AUTOSAR XML (schema 4-0-3)
package /ComponentTypes
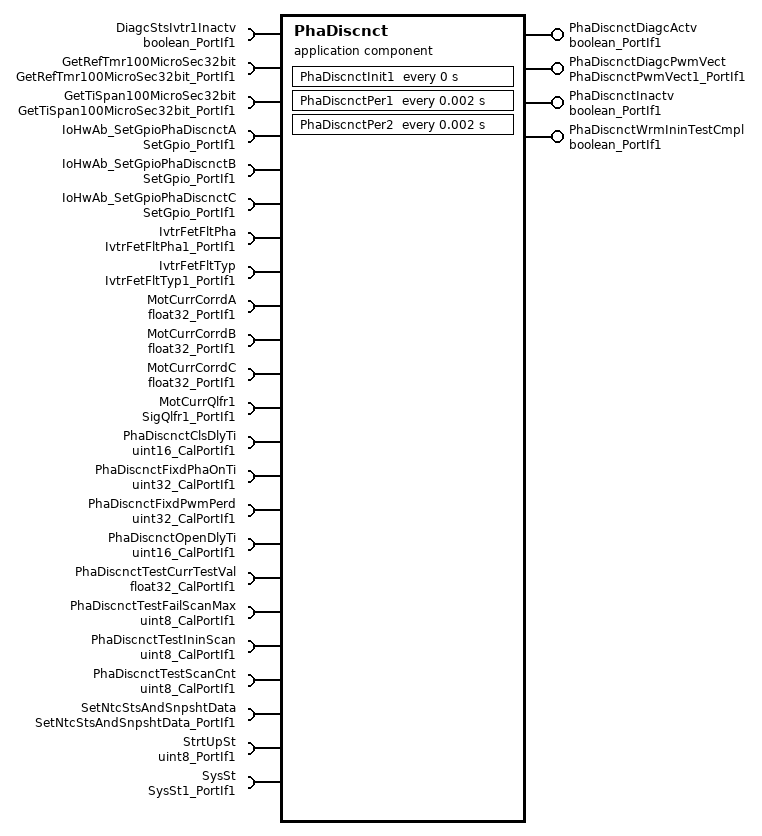
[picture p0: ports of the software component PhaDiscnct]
  application sw component type PhaDiscnct
    4 x provide port:
      PhaDiscnctDiagcActv: nonqueued-sender-com-spec{data-element=Logl, init-value=0}, provided-interface=boolean_PortIf1  # Signal used to signal request of control over Timer PWM on times
      PhaDiscnctDiagcPwmVect: nonqueued-sender-com-spec{data-element=Val, init-value=0}, provided-interface=PhaDiscnctPwmVect1_PortIf1
      PhaDiscnctInactv: nonqueued-sender-com-spec{data-element=Logl, init-value=0}, provided-interface=boolean_PortIf1  # Signal used to indicate that Phase Disconnect functionality is not active
      PhaDiscnctWrmIninTestCmpl: nonqueued-sender-com-spec{data-element=Logl, init-value=0}, provided-interface=boolean_PortIf1  # Signal used to indicate phase disconnect warm init test completed
    23 x require port:
      DiagcStsIvtr1Inactv: nonqueued-receiver-com-spec{data-element=Logl, filter=data-filter-type=ALWAYS, init-value=0}, required-interface=boolean_PortIf1  # Diagnostic Status Inverter 1 Inactive
      GetRefTmr100MicroSec32bit: client-com-spec=Oper, required-interface=GetRefTmr100MicroSec32bit_PortIf1  # System Time Server call
      GetTiSpan100MicroSec32bit: client-com-spec=Oper, required-interface=GetTiSpan100MicroSec32bit_PortIf1  # Calculate System Time Span Server call
      IoHwAb_SetGpioPhaDiscnctA: client-com-spec=Oper, required-interface=SetGpio_PortIf1
      IoHwAb_SetGpioPhaDiscnctB: client-com-spec=Oper, required-interface=SetGpio_PortIf1
      IoHwAb_SetGpioPhaDiscnctC: client-com-spec=Oper, required-interface=SetGpio_PortIf1
      IvtrFetFltPha: nonqueued-receiver-com-spec{data-element=Val, filter=data-filter-type=ALWAYS, init-value=0}, required-interface=IvtrFetFltPha1_PortIf1
      IvtrFetFltTyp: nonqueued-receiver-com-spec{data-element=Val, filter=data-filter-type=ALWAYS, init-value=0}, required-interface=IvtrFetFltTyp1_PortIf1
      MotCurrCorrdA: nonqueued-receiver-com-spec{data-element=Val, filter=data-filter-type=ALWAYS, init-value=0}, required-interface=float32_PortIf1  # Corrected Motor Current A
      MotCurrCorrdB: nonqueued-receiver-com-spec{data-element=Val, filter=data-filter-type=ALWAYS, init-value=0}, required-interface=float32_PortIf1  # Corrected Motor Current B
      MotCurrCorrdC: nonqueued-receiver-com-spec{data-element=Val, filter=data-filter-type=ALWAYS, init-value=0}, required-interface=float32_PortIf1  # Corrected Motor Current C
      MotCurrQlfr1: nonqueued-receiver-com-spec{data-element=Val, filter=data-filter-type=ALWAYS, init-value=0}, required-interface=SigQlfr1_PortIf1  # Motor Current Qualifier 1
      PhaDiscnctClsDlyTi: parameter-require-com-spec{init-value=40, parameter=Val}, required-interface=uint16_CalPortIf1  # hase Disconnect Time needed to set phase disconnect to close. Predefined Time required to close peripherials to set its steady stateDelay between transition from closing to close state 1Cnt = 100us
      PhaDiscnctFixdPhaOnTi: parameter-require-com-spec{init-value=6250, parameter=Val}, required-interface=uint32_CalPortIf1  # This calibration indicates PMW timer set of phase N (ON) time in PWM cycleCal is to set phase output PWM duty = PhaDiscnctFixdPhaOnTi/PhaDiscnctFixdPwmPerd
      PhaDiscnctFixdPwmPerd: parameter-require-com-spec{init-value=62500, parameter=Val}, required-interface=uint32_CalPortIf1  # Phase Disconnect Fixed PWM Period
      PhaDiscnctOpenDlyTi: parameter-require-com-spec{init-value=40, parameter=Val}, required-interface=uint16_CalPortIf1  # Phase Disconnect Time needed to recirculate current. Delay between transition from opening state to open 1Cnt=100us
      PhaDiscnctTestCurrTestVal: parameter-require-com-spec{init-value=20, parameter=Val}, required-interface=float32_CalPortIf1
      PhaDiscnctTestFailScanMax: parameter-require-com-spec{init-value=2, parameter=Val}, required-interface=uint8_CalPortIf1  # Maximum test fail scans required to set phase disconnect fault. Should be greater than 0, and shouldn''t be greater than PhaDiscnctTestScanCnt.
      PhaDiscnctTestIninScan: parameter-require-com-spec{init-value=3, parameter=Val}, required-interface=uint8_CalPortIf1  # Number of Tests scans, initialization of test.Time needed to set proper current in motor phase inductancetime is quantized in number of per1 scans scan*2ms.
      PhaDiscnctTestScanCnt: parameter-require-com-spec{init-value=4, parameter=Val}, required-interface=uint8_CalPortIf1  # Number of Tests performed during inital diagnostics interation. While scan counter is less than this calibration diagnostics is processed. Once scan counter reaches this value, diagnostics iteration sets pass status. Value should be greater than 0, and greater or equal to PhaDiscnctTestFailScanMax.
      SetNtcStsAndSnpshtData: client-com-spec=Oper, required-interface=SetNtcStsAndSnpshtData_PortIf1  # Set NTC Status And Snapshot Data
      StrtUpSt: nonqueued-receiver-com-spec{data-element=Val, filter=data-filter-type=ALWAYS, init-value=0}, required-interface=uint8_PortIf1
      SysSt: nonqueued-receiver-com-spec{data-element=Val, filter=data-filter-type=ALWAYS, init-value=3}, required-interface=SysSt1_PortIf1
    behavior PhaDiscnct_InternalBehavior
      ar-typed-per-instance-memorys:
        14 x data, all with sw-calibration-access=READ-ONLY:
          DiscnctClsTmr: type=uint32  # Var. Holds system time value latched during PhaDiscnct Closing. Used to calculate span which is condition to transit to Close
          DiscnctDiagCurrComp: type=uint8  # Bit coded status of Phase current comparision.
          DiscnctDiagFailScan: type=uint8  # Phase Disconnect Fail scans counter counts diagnostics fail occurences within test iteration
          DiscnctDiagFltSts: type=uint8  # Phase Disconnect Diagnostics Fault Status
          DiscnctDiagItrn: type=uint8  # Phase Disconnect Tests Iterator
          DiscnctDiagSt: type=uint8  # Instance State Diagnostics State Variable
          DiscnctDiagTestScan: type=uint8  # Phase Disconnect test scans countercounts function calls within particular test iteration
          DiscnctFltPrm: type=uint8  # Phase Disconnect Diagnostics Fault Parameter
          DiscnctOpenTmr: type=uint32  # Holds system time value latched during PhaDiscnct OpeningUsed to calculate span which is condition to transit to Open
          DiscnctSt: type=uint8  # Phase Disconnect Operation State
          dPhaDiscnctActvd: type=boolean  # Output Phase Disconnect Diagnostics Activated state
          dPhaDiscnctCmd: type=uint8  # Output Phase Disconnect I/O command in bit positive logicPhase A-bit0 ... Phase C-bit2
          PrevDiscnctCmd: type=uint8  # Memory signal phase disconnect command used for signal change determination
          WrmIninTestCmpl: type=boolean  # Warm init test completed
      timing event PhaDiscnct_InitEvent: start-on-event=PhaDiscnctInit1, period=0
      timing event TMT_PhaDiscnctPer1: start-on-event=PhaDiscnctPer1, period=0.002
      timing event TMT_PhaDiscnctPer2: start-on-event=PhaDiscnctPer2, period=0.002
      runnable PhaDiscnctInit1
        sync call SC_IoHwAb_SetGpioPhaDiscnctA_Oper: operation=IoHwAb_SetGpioPhaDiscnctA.Oper, timeout=0
        sync call SC_IoHwAb_SetGpioPhaDiscnctB_Oper: operation=IoHwAb_SetGpioPhaDiscnctB.Oper, timeout=0
        sync call SC_IoHwAb_SetGpioPhaDiscnctC_Oper: operation=IoHwAb_SetGpioPhaDiscnctC.Oper, timeout=0
      runnable PhaDiscnctPer1
        data-receive-point-by-arguments:
          7 x access:
            REC_DiagcStsIvtr1Inactv_Logl: accessed-variable=DiagcStsIvtr1Inactv.Logl
            REC_IvtrFetFltTyp_Val: accessed-variable=IvtrFetFltTyp.Val
            REC_MotCurrCorrdA_Val: accessed-variable=MotCurrCorrdA.Val
            REC_MotCurrCorrdB_Val: accessed-variable=MotCurrCorrdB.Val
            REC_MotCurrCorrdC_Val: accessed-variable=MotCurrCorrdC.Val
            REC_MotCurrQlfr1_Val: accessed-variable=MotCurrQlfr1.Val
            REC_StrtUpSt_Val: accessed-variable=StrtUpSt.Val
        data-send-points:
          access SEND_PhaDiscnctDiagcActv_Logl: accessed-variable=PhaDiscnctDiagcActv.Logl
          access SEND_PhaDiscnctDiagcPwmVect_Val: accessed-variable=PhaDiscnctDiagcPwmVect.Val
        4 x sync call, all with timeout=0:
          SC_IoHwAb_SetGpioPhaDiscnctA_Oper: operation=IoHwAb_SetGpioPhaDiscnctA.Oper
          SC_IoHwAb_SetGpioPhaDiscnctB_Oper: operation=IoHwAb_SetGpioPhaDiscnctB.Oper
          SC_IoHwAb_SetGpioPhaDiscnctC_Oper: operation=IoHwAb_SetGpioPhaDiscnctC.Oper
          SC_SetNtcStsAndSnpshtData_Oper: operation=SetNtcStsAndSnpshtData.Oper
      runnable PhaDiscnctPer2  # Phase Disconnect provides mechanism of disconnecting Motor Phases from system in order to prevent generation of unintended negative or positive motor torque. Phase Disconnect is controlled by System State and Motor Control Gate Driver FET fault signals. Phase Disconnect functionality provides support for loss of assist mitigation.
        data-receive-point-by-arguments:
          4 x access:
            REC_IvtrFetFltPha_Val: accessed-variable=IvtrFetFltPha.Val
            REC_IvtrFetFltTyp_Val: accessed-variable=IvtrFetFltTyp.Val
            REC_StrtUpSt_Val: accessed-variable=StrtUpSt.Val
            REC_SysSt_Val: accessed-variable=SysSt.Val
        data-send-points:
          access SEND_PhaDiscnctInactv_Logl: accessed-variable=PhaDiscnctInactv.Logl
          access SEND_PhaDiscnctWrmIninTestCmpl_Logl: accessed-variable=PhaDiscnctWrmIninTestCmpl.Logl
        5 x sync call, all with timeout=0:
          SC_GetRefTmr100MicroSec32bit_Oper: operation=GetRefTmr100MicroSec32bit.Oper
          SC_GetTiSpan100MicroSec32bit_Oper: operation=GetTiSpan100MicroSec32bit.Oper
          SC_IoHwAb_SetGpioPhaDiscnctA_Oper: operation=IoHwAb_SetGpioPhaDiscnctA.Oper
          SC_IoHwAb_SetGpioPhaDiscnctB_Oper: operation=IoHwAb_SetGpioPhaDiscnctB.Oper
          SC_IoHwAb_SetGpioPhaDiscnctC_Oper: operation=IoHwAb_SetGpioPhaDiscnctC.Oper
  swc implementation PhaDiscnct_Implementation: behavior=PhaDiscnct_InternalBehavior
    code-descriptors:
      code Default: artifact-descriptors=autosar-engineering-object={short-label=Default, category=SWSRC}
